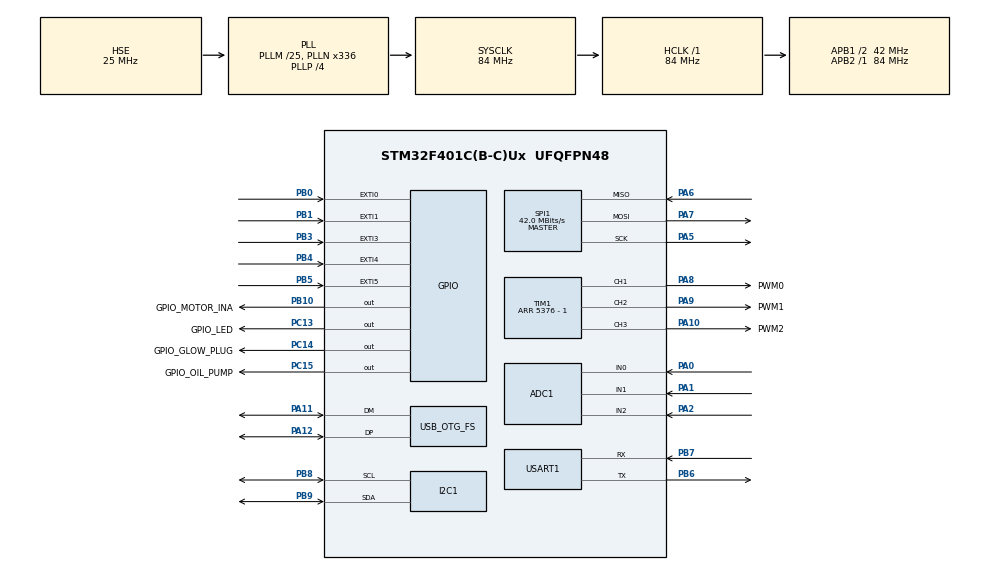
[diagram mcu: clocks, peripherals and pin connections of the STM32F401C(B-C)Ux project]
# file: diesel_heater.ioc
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Mcu.Family=STM32F4
PA6.Mode=Full_Duplex_Master
USB_DEVICE.CLASS_NAME_FS=CDC
Dma.I2C1_TX.0.Instance=DMA1_Stream6
RCC.CortexFreq_Value=84000000
NVIC.I2C1_EV_IRQn=true\:0\:0\:false\:false\:true\:true\:true
SPI1.VirtualType=VM_MASTER
Dma.I2C1_TX.0.PeriphDataAlignment=DMA_PDATAALIGN_BYTE
PB4.GPIO_ModeDefaultEXTI=GPIO_MODE_IT_RISING_FALLING
PA10.GPIO_PuPd=GPIO_NOPULL
SH.ADCx_IN2.0=ADC1_IN2,IN2
Dma.I2C1_TX.0.Direction=DMA_MEMORY_TO_PERIPH
NVIC.EXTI3_IRQn=true\:0\:0\:false\:false\:true\:true\:true
PA11.Mode=Device_Only
PB3.GPIO_ModeDefaultEXTI=GPIO_MODE_IT_RISING_FALLING
PC15-OSC32_OUT.GPIO_Label=GPIO_OIL_PUMP
RCC.SYSCLKSource=RCC_SYSCLKSOURCE_PLLCLK
ProjectManager.StackSize=0x400
NVIC.ADC_IRQn=true\:0\:0\:false\:false\:true\:true\:true
NVIC.EXTI1_IRQn=true\:0\:0\:false\:false\:true\:true\:true
PA12.Signal=USB_OTG_FS_DP
PH0\ -\ OSC_IN.Signal=RCC_OSC_IN
SPI1.Direction=SPI_DIRECTION_2LINES
PB1.GPIO_PuPd=GPIO_PULLUP
RCC.HCLKFreq_Value=84000000
RCC.APB2TimFreq_Value=84000000
PB1.GPIO_ModeDefaultEXTI=GPIO_MODE_IT_RISING_FALLING
PB6.Signal=USART1_TX
PB6.Mode=Asynchronous
SPI1.CalculateBaudRate=42.0 MBits/s
Dma.I2C1_TX.0.Priority=DMA_PRIORITY_LOW
RCC.AHBFreq_Value=84000000
ADC1.Channel-0\#ChannelRegularConversion=ADC_CHANNEL_0
RCC.HSE_VALUE=25000000
PC13-ANTI_TAMP.Signal=GPIO_Output
PB3.GPIO_PuPd=GPIO_PULLUP
TIM1.Channel-PWM\ Generation1\ CH1=TIM_CHANNEL_1
PA14.Mode=Serial_Wire
Dma.I2C1_TX.0.MemInc=DMA_MINC_ENABLE
PA10.GPIO_Label=PWM2
PB7.Signal=USART1_RX
PA8.Signal=S_TIM1_CH1
SH.ADCx_IN0.0=ADC1_IN0,IN0
NVIC.I2C1_ER_IRQn=true\:0\:0\:false\:false\:true\:true\:true
ADC1.SamplingTime-0\#ChannelRegularConversion=ADC_SAMPLETIME_3CYCLES
Dma.I2C1_TX.0.PeriphInc=DMA_PINC_DISABLE
Mcu.Package=UFQFPN48
PB9.Signal=I2C1_SDA
PB1.Signal=GPXTI1
PA6.Signal=SPI1_MISO
NVIC.OTG_FS_IRQn=true\:0\:0\:false\:false\:true\:true\:true
PA10.Signal=S_TIM1_CH3
USB_OTG_FS.VirtualMode=Device_Only
Dma.I2C1_TX.0.MemDataAlignment=DMA_MDATAALIGN_BYTE
SH.ADCx_IN1.0=ADC1_IN1,IN1
RCC.APB1TimFreq_Value=84000000
PC14-OSC32_IN.GPIO_Label=GPIO_GLOW_PLUG
TIM1.Period=5376 - 1
Dma.I2C1_TX.0.Mode=DMA_NORMAL
NVIC.USART1_IRQn=true\:0\:0\:false\:false\:true\:true\:true
Dma.Request0=I2C1_TX
NVIC.DMA1_Stream6_IRQn=true\:0\:0\:false\:false\:true\:false\:true
SPI1.BaudRatePrescaler=SPI_BAUDRATEPRESCALER_2
PB4.Signal=GPXTI4
PA5.Mode=Full_Duplex_Master
PB5.GPIO_ModeDefaultEXTI=GPIO_MODE_IT_RISING_FALLING
NVIC.EXTI4_IRQn=true\:0\:0\:false\:false\:true\:true\:true
ADC1.Rank-0\#ChannelRegularConversion=1
PA7.Mode=Full_Duplex_Master
USB_DEVICE.VirtualModeFS=Cdc_FS
PC13-ANTI_TAMP.GPIO_Label=GPIO_LED
PA9.GPIO_Label=PWM1
PH1\ -\ OSC_OUT.Mode=HSE-External-Oscillator
RCC.APB1CLKDivider=RCC_HCLK_DIV2
PC14-OSC32_IN.Signal=GPIO_Output
PA9.GPIO_PuPd=GPIO_NOPULL
PA0-WKUP.Signal=ADCx_IN0
PA13.Signal=SYS_JTMS-SWDIO
PH0\ -\ OSC_IN.Mode=HSE-External-Oscillator
PA8.GPIO_Label=PWM0
SH.S_TIM1_CH1.0=TIM1_CH1,PWM Generation1 CH1
ProjectManager.TargetToolchain=Makefile
PB10.GPIO_Label=GPIO_MOTOR_INA
I2C1.I2C_Mode=I2C_Fast
VP_USB_DEVICE_VS_USB_DEVICE_CDC_FS.Mode=CDC_FS
PB9.Mode=I2C
PA9.Signal=S_TIM1_CH2
TIM1.Channel-PWM\ Generation2\ CH2=TIM_CHANNEL_2
PB4.GPIO_PuPd=GPIO_PULLUP
RCC.LSE_VALUE=32768
PC15-OSC32_OUT.Signal=GPIO_Output
PA1.Signal=ADCx_IN1
PB10.Signal=GPIO_Output
PA5.Signal=SPI1_SCK
PH1\ -\ OSC_OUT.Signal=RCC_OSC_OUT
board=custom
RCC.VCOOutputFreq_Value=336000000
NVIC.SPI1_IRQn=true\:0\:0\:false\:false\:true\:true\:true
RCC.APB2Freq_Value=84000000
SH.S_TIM1_CH2.0=TIM1_CH2,PWM Generation2 CH2
SPI1.Mode=SPI_MODE_MASTER
PA13.Mode=Serial_Wire
Mcu.Name=STM32F401C(B-C)Ux
PA2.Signal=ADCx_IN2
RCC.48MHZClocksFreq_Value=48000000
PB3.Signal=GPXTI3
NVIC.EXTI0_IRQn=true\:0\:0\:false\:false\:true\:true\:true
RCC.SYSCLKFreq_VALUE=84000000
PB5.Signal=GPXTI5
ADC1.master=1
PA12.Mode=Device_Only
PB5.GPIO_PuPd=GPIO_PULLUP
USART1.VirtualMode=VM_ASYNC
PB7.Mode=Asynchronous
PA11.Signal=USB_OTG_FS_DM
NVIC.EXTI9_5_IRQn=true\:0\:0\:false\:false\:true\:true\:true
PA14.Signal=SYS_JTCK-SWCLK
ProjectManager.HeapSize=0x200
SH.S_TIM1_CH3.0=TIM1_CH3,PWM Generation3 CH3
RCC.HSI_VALUE=16000000
PA8.GPIO_PuPd=GPIO_NOPULL
RCC.PLLP=RCC_PLLP_DIV4
RCC.PLLQ=7
NVIC.PriorityGroup=NVIC_PRIORITYGROUP_4
ADC1.NbrOfConversionFlag=1
Dma.I2C1_TX.0.FIFOMode=DMA_FIFOMODE_DISABLE
RCC.PLLM=25
PB8.Mode=I2C
RCC.PLLN=336
PB8.Signal=I2C1_SCL
TIM1.Channel-PWM\ Generation3\ CH3=TIM_CHANNEL_3
RCC.APB1Freq_Value=42000000
PB0.Signal=GPXTI0
USB_DEVICE.VirtualMode=Cdc
PB0.GPIO_PuPd=GPIO_NOPULL
PA7.Signal=SPI1_MOSI

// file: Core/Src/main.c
/* USER CODE BEGIN Header */
/**
  ******************************************************************************
  * @file           : main.c
  * @brief          : Main program body
  ******************************************************************************
  * @attention
  *
  * <h2><center>&copy; Copyright (c) 2021 STMicroelectronics.
  * All rights reserved.</center></h2>
  *
  * This software component is licensed by ST under Ultimate Liberty license
  * SLA0044, the "License"; You may not use this file except in compliance with
  * the License. You may obtain a copy of the License at:
  *                             www.st.com/SLA0044
  *
  ******************************************************************************
  */
/* USER CODE END Header */
#include "main.h"
#include "adc.h"
#include "dma.h"
#include "i2c.h"
#include "spi.h"
#include "tim.h"
#include "usart.h"
#include "usb_device.h"
#include "gpio.h"

/* USER CODE BEGIN Includes */
#include "app.h"
/* USER CODE END Includes */

void SystemClock_Config(void);

int main(void)
{

  /* MCU Configuration--------------------------------------------------------*/

  /* Reset of all peripherals, Initializes the Flash interface and the Systick. */
  HAL_Init();

  /* Configure the system clock */
  SystemClock_Config();

  /* Initialize all configured peripherals */
  MX_GPIO_Init();
  MX_DMA_Init();
  MX_I2C1_Init();
  MX_ADC1_Init();
  MX_SPI1_Init();
  MX_TIM1_Init();
  MX_USART1_UART_Init();
  MX_USB_DEVICE_Init();
  /* USER CODE BEGIN 2 */
  app_init();
  /* USER CODE END 2 */

  /* Infinite loop */
  while (1)
  {

    /* USER CODE BEGIN 3 */
    app_run();
#if 0
    HAL_Delay(1000);
    HAL_GPIO_TogglePin(GPIO_LED_GPIO_Port, GPIO_LED_Pin);
#endif
  }
  /* USER CODE END 3 */
}

void SystemClock_Config(void)
{
  RCC_OscInitTypeDef RCC_OscInitStruct = {0};
  RCC_ClkInitTypeDef RCC_ClkInitStruct = {0};

  /** Configure the main internal regulator output voltage
  */
  __HAL_RCC_PWR_CLK_ENABLE();
  __HAL_PWR_VOLTAGESCALING_CONFIG(PWR_REGULATOR_VOLTAGE_SCALE2);
  /** Initializes the RCC Oscillators according to the specified parameters
  * in the RCC_OscInitTypeDef structure.
  */
  RCC_OscInitStruct.OscillatorType = RCC_OSCILLATORTYPE_HSE;
  RCC_OscInitStruct.HSEState = RCC_HSE_ON;
  RCC_OscInitStruct.PLL.PLLState = RCC_PLL_ON;
  RCC_OscInitStruct.PLL.PLLSource = RCC_PLLSOURCE_HSE;
  RCC_OscInitStruct.PLL.PLLM = 25;
  RCC_OscInitStruct.PLL.PLLN = 336;
  RCC_OscInitStruct.PLL.PLLP = RCC_PLLP_DIV4;
  RCC_OscInitStruct.PLL.PLLQ = 7;
  if (HAL_RCC_OscConfig(&RCC_OscInitStruct) != HAL_OK)
  {
    Error_Handler();
  }
  /** Initializes the CPU, AHB and APB buses clocks
  */
  RCC_ClkInitStruct.ClockType = RCC_CLOCKTYPE_HCLK|RCC_CLOCKTYPE_SYSCLK
                              |RCC_CLOCKTYPE_PCLK1|RCC_CLOCKTYPE_PCLK2;
  RCC_ClkInitStruct.SYSCLKSource = RCC_SYSCLKSOURCE_PLLCLK;
  RCC_ClkInitStruct.AHBCLKDivider = RCC_SYSCLK_DIV1;
  RCC_ClkInitStruct.APB1CLKDivider = RCC_HCLK_DIV2;
  RCC_ClkInitStruct.APB2CLKDivider = RCC_HCLK_DIV1;

  if (HAL_RCC_ClockConfig(&RCC_ClkInitStruct, FLASH_LATENCY_2) != HAL_OK)
  {
    Error_Handler();
  }
}

void Error_Handler(void)
{
  __disable_irq();
  while (1)
  {
  }
}

/************************ (C) COPYRIGHT STMicroelectronics *****END OF FILE****/
